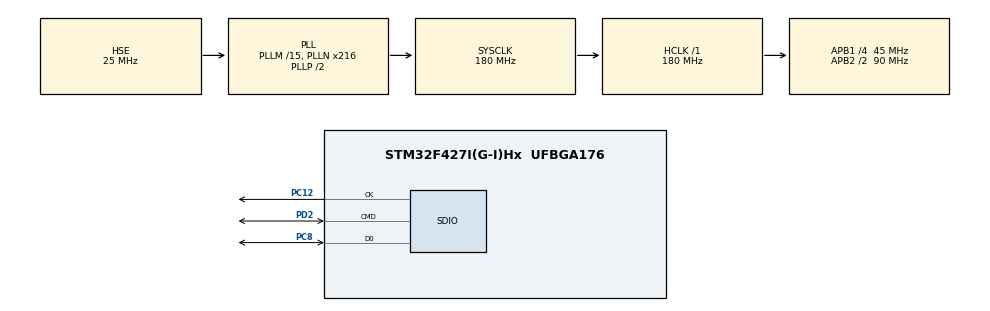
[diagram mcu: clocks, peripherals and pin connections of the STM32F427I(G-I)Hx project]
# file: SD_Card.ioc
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FATFS._CODE_PAGE=936
FATFS._FS_LOCK=2
FATFS._MAX_SS=4096
FATFS._USE_CHMOD=1
FATFS._USE_EXPAND=1
FATFS._USE_FIND=1
FATFS._USE_FORWARD=1
FATFS._USE_LABEL=1
FATFS._USE_LFN=2
Mcu.Family=STM32F4
Mcu.Name=STM32F427I(G-I)Hx
Mcu.Package=UFBGA176
NVIC.PriorityGroup=NVIC_PRIORITYGROUP_4
NVIC.SDIO_IRQn=true\:0\:0\:false\:false\:true\:true\:true\:true
PA13.Mode=Serial_Wire
PA13.Signal=SYS_JTMS-SWDIO
PA14.Mode=Serial_Wire
PA14.Signal=SYS_JTCK-SWCLK
PC12.Mode=SD_1_bit
PC12.Signal=SDIO_CK
PC8.Mode=SD_1_bit
PC8.Signal=SDIO_D0
PD2.Mode=SD_1_bit
PD2.Signal=SDIO_CMD
PH0/OSC_IN.Mode=HSE-External-Oscillator
PH0/OSC_IN.Signal=RCC_OSC_IN
PH1/OSC_OUT.Mode=HSE-External-Oscillator
PH1/OSC_OUT.Signal=RCC_OSC_OUT
ProjectManager.HeapSize=0x200
ProjectManager.StackSize=0x400
ProjectManager.TargetToolchain=EWARM V8.32
RCC.48MHZClocksFreq_Value=45000000
RCC.AHBFreq_Value=180000000
RCC.APB1CLKDivider=RCC_HCLK_DIV4
RCC.APB1Freq_Value=45000000
RCC.APB1TimFreq_Value=90000000
RCC.APB2CLKDivider=RCC_HCLK_DIV2
RCC.APB2Freq_Value=90000000
RCC.APB2TimFreq_Value=180000000
RCC.CortexFreq_Value=180000000
RCC.HCLKFreq_Value=180000000
RCC.HSE_VALUE=25000000
RCC.HSI_VALUE=16000000
RCC.LSE_VALUE=32768
RCC.PLLM=15
RCC.PLLN=216
RCC.PLLQ=8
RCC.PLLSourceVirtual=RCC_PLLSOURCE_HSE
RCC.SYSCLKFreq_VALUE=180000000
RCC.SYSCLKSource=RCC_SYSCLKSOURCE_PLLCLK
RCC.VCOOutputFreq_Value=360000000
SDIO.ClockDiv=0
VP_FATFS_VS_Generic.Mode=User_defined
VP_FATFS_VS_SDIO.Mode=SDIO
board=custom

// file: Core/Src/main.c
/* USER CODE BEGIN Header */
/**
  ******************************************************************************
  * @file           : main.c
  * @brief          : Main program body
  ******************************************************************************
  * @attention
  *
  * Copyright (c) 2024 STMicroelectronics.
  * All rights reserved.
  *
  * This software is licensed under terms that can be found in the LICENSE file
  * in the root directory of this software component.
  * If no LICENSE file comes with this software, it is provided AS-IS.
  *
  ******************************************************************************
  */
/* USER CODE END Header */
#include "main.h"
#include "fatfs.h"
#include "sdio.h"
#include "gpio.h"

/* USER CODE BEGIN Includes */

#include "ffconf.h"
#include "LogSystem.h"

/* USER CODE END Includes */

/* USER CODE BEGIN PV */

DWORD FreeCluster;
FATFS* SDFatFS_Pointer = &SDFatFS;
int status[3];

uint8_t SDbuffer[_MAX_SS];
uint32_t WriteByte;

/* USER CODE END PV */

void SystemClock_Config(void);

int main(void)
{

  /* MCU Configuration--------------------------------------------------------*/

  /* Reset of all peripherals, Initializes the Flash interface and the Systick. */
  HAL_Init();

  /* Configure the system clock */
  SystemClock_Config();

  /* Initialize all configured peripherals */
  MX_GPIO_Init();
  MX_SDIO_SD_Init();
  MX_FATFS_Init();
  /* USER CODE BEGIN 2 */

  BSP_SD_Init();

  // status[0] = f_mount(&SDFatFS, (const TCHAR*)SDPath, 0);
  // status[1] = f_mkfs((const TCHAR*)SDPath, FM_ANY, 0, SDbuffer, sizeof(SDbuffer));
  // if (status[0] == FR_OK && status[1] == FR_OK) {
  //   status[2] = f_open(&SDFile, "Log.txt", FA_CREATE_ALWAYS | FA_WRITE);
  //   f_write(&SDFile, "Hello World", sizeof("Hello World"), (void*)&WriteByte);
  //   f_close(&SDFile);
  // }

  LogSystem_Init();
  LogSystem_CreateFile("text.txt");
  LogSystem_Write("Data: ", 100.23);
  LogSystem_Write("abc ", 112.34);
  LogSystem_Write("abc ", 112.34);
  // LogSystem_WriteNumber(123.45);
  LogSystem_CloseFile();

  /* USER CODE END 2 */

  /* Infinite loop */
  while (1)
  {

  }
}

void SystemClock_Config(void)
{
  RCC_OscInitTypeDef RCC_OscInitStruct = {0};
  RCC_ClkInitTypeDef RCC_ClkInitStruct = {0};

  /** Configure the main internal regulator output voltage
  */
  __HAL_RCC_PWR_CLK_ENABLE();
  __HAL_PWR_VOLTAGESCALING_CONFIG(PWR_REGULATOR_VOLTAGE_SCALE1);

  /** Initializes the RCC Oscillators according to the specified parameters
  * in the RCC_OscInitTypeDef structure.
  */
  RCC_OscInitStruct.OscillatorType = RCC_OSCILLATORTYPE_HSE;
  RCC_OscInitStruct.HSEState = RCC_HSE_ON;
  RCC_OscInitStruct.PLL.PLLState = RCC_PLL_ON;
  RCC_OscInitStruct.PLL.PLLSource = RCC_PLLSOURCE_HSE;
  RCC_OscInitStruct.PLL.PLLM = 15;
  RCC_OscInitStruct.PLL.PLLN = 216;
  RCC_OscInitStruct.PLL.PLLP = RCC_PLLP_DIV2;
  RCC_OscInitStruct.PLL.PLLQ = 8;
  if (HAL_RCC_OscConfig(&RCC_OscInitStruct) != HAL_OK)
  {
    Error_Handler();
  }

  /** Activate the Over-Drive mode
  */
  if (HAL_PWREx_EnableOverDrive() != HAL_OK)
  {
    Error_Handler();
  }

  /** Initializes the CPU, AHB and APB buses clocks
  */
  RCC_ClkInitStruct.ClockType = RCC_CLOCKTYPE_HCLK|RCC_CLOCKTYPE_SYSCLK
                              |RCC_CLOCKTYPE_PCLK1|RCC_CLOCKTYPE_PCLK2;
  RCC_ClkInitStruct.SYSCLKSource = RCC_SYSCLKSOURCE_PLLCLK;
  RCC_ClkInitStruct.AHBCLKDivider = RCC_SYSCLK_DIV1;
  RCC_ClkInitStruct.APB1CLKDivider = RCC_HCLK_DIV4;
  RCC_ClkInitStruct.APB2CLKDivider = RCC_HCLK_DIV2;

  if (HAL_RCC_ClockConfig(&RCC_ClkInitStruct, FLASH_LATENCY_5) != HAL_OK)
  {
    Error_Handler();
  }
}

void Error_Handler(void)
{
  __disable_irq();
  while (1)
  {
  }
}
